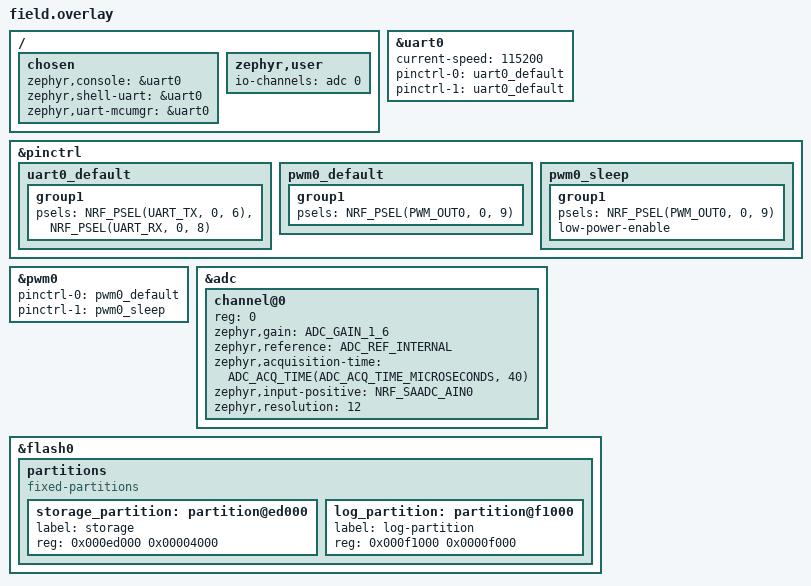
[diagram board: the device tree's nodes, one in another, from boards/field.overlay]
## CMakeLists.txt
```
cmake_minimum_required(VERSION 3.20.0)
find_package(Zephyr REQUIRED HINTS $ENV{ZEPHYR_BASE})
project(smart_lock)
target_sources(app PRIVATE
    src/main.c
    src/lock_hw_zephyr.c
    src/ble_gatt.c
    src/motor.c
    src/battery.c
    src/build_info.c
    src/trinity_wdt.c
    src/trinity_canary.c
    src/trinity_flash.c
    src/trinity_stats.c
    src/trinity_fault.c
    src/trinity_boot.c
)

target_include_directories(app PRIVATE
    ../../include
)
```

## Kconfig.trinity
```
# ==============================================================================
# Kconfig.trinity
# Source from each Zephyr board's root Kconfig: source "Kconfig.trinity"
# IDF and STM32 boards do not use this file -- use CMakeLists.txt instead.
# ==============================================================================

config TRINITY_CHIP_NRF52840
    bool "Trinity: nRF52840 (Zephyr)"
    help
      Selects nRF52840-specific Trinity behaviour in trinity_log_zephyr_nrf.c:
        - Cortex-M4 fault frame (CFSR/HFSR/MMFAR/BFAR/PC/LR/CYC)
        - Boot reason from NRF_POWER->RESETREAS (read + cleared by main)
        - Flash mutex active (NVMC is single-writer, no concurrent access)
        - Pre-init canary in .noinit via SYS_INIT(PRE_KERNEL_1)
        - Heap-allocated stat buffer (avoids .noinit BSS overlap)
        - Bench mode: feeds bootloader WDT channel 0 (cannot be disabled)
      Boards: reed-sensor, smart-lock, smart-light
      Set in prj.conf: CONFIG_TRINITY_CHIP_NRF52840=y

config TRINITY_CHIP_ESP32C3
    bool "Trinity: ESP32-C3 (Zephyr)"
    help
      Selects ESP32-C3-specific Trinity behaviour in trinity_log_zephyr_esp.c:
        - RISC-V fault frame (mepc/ra instead of pc/lr)
        - No flash mutex (ESP32-C3 flash driver serializes internally)
        - Pre-init canary in .noinit via SYS_INIT(PRE_KERNEL_1)
        - Heap-allocated stat buffer (same .noinit overlap protection)
        - Bench mode: WDT skipped entirely (OpenOCD is safety net)
      Boards: pir
      Set in prj.conf: CONFIG_TRINITY_CHIP_ESP32C3=y
```

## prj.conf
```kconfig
# ========================= CORE ==============================================
CONFIG_TRINITY_CHIP_NRF52840=y
CONFIG_PRINTK=y
CONFIG_CONSOLE=y
CONFIG_SERIAL=y
CONFIG_BUILD_OUTPUT_UF2=y

# ========================= HARDWARE ==========================================
CONFIG_ADC=y
CONFIG_PWM=y

# ========================= FLASH / NVS =======================================
CONFIG_FLASH=y
CONFIG_FLASH_MAP=y
CONFIG_FLASH_PAGE_LAYOUT=y
CONFIG_NVS=y
CONFIG_SETTINGS=y
CONFIG_SETTINGS_NVS=y
CONFIG_MPU_ALLOW_FLASH_WRITE=y
CONFIG_STREAM_FLASH=y
CONFIG_SOC_FLASH_NRF_PARTIAL_ERASE=y
CONFIG_SOC_FLASH_NRF_RADIO_SYNC_TICKER=y

# ========================= BLUETOOTH =========================================
CONFIG_BT=y
CONFIG_BT_PERIPHERAL=y
CONFIG_BT_DEVICE_NAME="SmartLock"
CONFIG_BT_GATT_SERVICE_CHANGED=y
CONFIG_BT_LOG_LEVEL_OFF=y

# ========================= STACK SIZES =======================================
CONFIG_ISR_STACK_SIZE=8192
CONFIG_SYSTEM_WORKQUEUE_STACK_SIZE=3072
CONFIG_MAIN_STACK_SIZE=8192
CONFIG_LOG_PROCESS_THREAD_STACK_SIZE=1024

# ========================= FAULT COVERAGE ====================================
CONFIG_HW_STACK_PROTECTION=y
CONFIG_FAULT_DUMP=2
CONFIG_FRAME_POINTER=y
CONFIG_REBOOT=y

# ========================= LOGGING ===========================================
CONFIG_LOG=y
CONFIG_LOG_DEFAULT_LEVEL=3
CONFIG_LOG_MODE_DEFERRED=y
CONFIG_LOG_BUFFER_SIZE=16384

# ========================= THREAD VISIBILITY =================================
CONFIG_THREAD_NAME=y
CONFIG_THREAD_STACK_INFO=y
CONFIG_INIT_STACKS=y

# ========================= TRINITY WATCHDOG ==================================
CONFIG_WATCHDOG=y

# ========================= TRINITY HEAP STATS ================================
CONFIG_SYS_HEAP_RUNTIME_STATS=y
CONFIG_HEAP_MEM_POOL_SIZE=4096

# ========================= TRINITY THREAD STATS ==============================
CONFIG_THREAD_ANALYZER=y
CONFIG_THREAD_ANALYZER_USE_PRINTK=n
CONFIG_THREAD_ANALYZER_AUTO=n
CONFIG_THREAD_RUNTIME_STATS=y
CONFIG_WDT_DISABLE_AT_BOOT=n
```

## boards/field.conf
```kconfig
CONFIG_UART_CONSOLE=y
CONFIG_UART_INTERRUPT_DRIVEN=y
CONFIG_NRFX_UARTE0=y
CONFIG_WDT_DISABLE_AT_BOOT=y
CONFIG_WATCHDOG=y
CONFIG_USB_DEVICE_STACK_NEXT=n
CONFIG_USBD_CDC_ACM_CLASS=n
CONFIG_USB_DEVICE_STACK=n
CONFIG_USE_SEGGER_RTT=n
CONFIG_RTT_CONSOLE=n
CONFIG_LOG_BACKEND_RTT=n
```

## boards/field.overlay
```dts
/*******************************************************************************
 * \file field.overlay
 * \author MichaelLynnCSU (https://github.com/MichaelLynnCSU)
 * \date 01-01-2025
 *
 * \brief Field mode devicetree overlay for Pro Micro nRF52840 smart lock.
 *
 * \note    P0.29 vbat-div-en removed (2026-04-27):
 *          Low-side GND switch removed from hardware. Divider hardwired
 *          directly to GND. P0.29 node removed from overlay.
 *******************************************************************************/
/delete-node/ &storage_partition;

/ {
    chosen {
        zephyr,console = &uart0;
        zephyr,shell-uart = &uart0;
        zephyr,uart-mcumgr = &uart0;
    };

    zephyr,user {
        io-channels = <&adc 0>;
    };
};

&uart0 {
    status = "okay";
    current-speed = <115200>;
    pinctrl-0 = <&uart0_default>;
    pinctrl-1 = <&uart0_default>;
    pinctrl-names = "default", "sleep";
};

&pinctrl {
    uart0_default: uart0_default {
        group1 {
            psels = <NRF_PSEL(UART_TX, 0, 6)>,
                    <NRF_PSEL(UART_RX, 0, 8)>;
        };
    };
    pwm0_default: pwm0_default {
        group1 {
            psels = <NRF_PSEL(PWM_OUT0, 0, 9)>;
        };
    };
    pwm0_sleep: pwm0_sleep {
        group1 {
            psels = <NRF_PSEL(PWM_OUT0, 0, 9)>;
            low-power-enable;
        };
    };
};

&pwm0 {
    status = "okay";
    pinctrl-0 = <&pwm0_default>;
    pinctrl-1 = <&pwm0_sleep>;
    pinctrl-names = "default", "sleep";
};

&adc {
    status = "okay";
    #address-cells = <1>;
    #size-cells = <0>;
    channel@0 {
        reg = <0>;
        zephyr,gain = "ADC_GAIN_1_6";
        zephyr,reference = "ADC_REF_INTERNAL";
        zephyr,acquisition-time = <ADC_ACQ_TIME(ADC_ACQ_TIME_MICROSECONDS, 40)>;
        zephyr,input-positive = <NRF_SAADC_AIN0>; /* P0.02 -- Vbat/3 via 200k/100k divider */
        zephyr,resolution = <12>;
    };
};

&flash0 {
    partitions {
        compatible = "fixed-partitions";
        #address-cells = <1>;
        #size-cells = <1>;
        storage_partition: partition@ed000 {
            label = "storage";
            reg = <0x000ed000 0x00004000>;
        };
        log_partition: partition@f1000 {
            label = "log-partition";
            reg = <0x000f1000 0x0000f000>;
        };
    };
};
```

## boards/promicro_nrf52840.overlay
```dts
/*******************************************************************************
 * \file promicro_nrf52840.overlay
 * \author MichaelLynnCSU (https://github.com/MichaelLynnCSU)
 * \date 01-01-2025
 *
 * \brief Base devicetree overlay for Pro Micro nRF52840 smart lock node.
 *
 * \details Configures:
 *          - ADC channel 0: P0.02 (AIN0) 12-bit, 1/6 gain, internal ref
 *          - PWM0: P0.09 motor control
 *          - Flash partitions:
 *            storage_partition @ 0xED000 (16KB) NVS settings
 *            log_partition     @ 0xF1000 (60KB) flash event log
 *
 * \note    P0.29 vbat-div-en removed (2026-04-27):
 *          Low-side GND switch removed from hardware. Divider bottom
 *          resistor hardwired directly to GND. P0.29 node removed.
 *          21uA quiescent draw negligible vs motor and BLE current.
 *******************************************************************************/
/delete-node/ &storage_partition;

/ {
    zephyr,user {
        io-channels = <&adc 0>;
    };
};

&pwm0 {
    status = "okay";
    pinctrl-0 = <&pwm0_default>;
    pinctrl-1 = <&pwm0_sleep>;
    pinctrl-names = "default", "sleep";
};

&pinctrl {
    pwm0_default: pwm0_default {
        group1 {
            psels = <NRF_PSEL(PWM_OUT0, 0, 9)>;
        };
    };
    pwm0_sleep: pwm0_sleep {
        group1 {
            psels = <NRF_PSEL(PWM_OUT0, 0, 9)>;
            low-power-enable;
        };
    };
};

&adc {
    status = "okay";
    #address-cells = <1>;
    #size-cells = <0>;
    channel@0 {
        reg = <0>;
        zephyr,gain = "ADC_GAIN_1_6";
        zephyr,reference = "ADC_REF_INTERNAL";
        zephyr,acquisition-time = <ADC_ACQ_TIME(ADC_ACQ_TIME_MICROSECONDS, 40)>;
        zephyr,input-positive = <NRF_SAADC_AIN0>; /* P0.02 -- Vbat/3 via 200k/100k divider */
        zephyr,resolution = <12>;
    };
};

&flash0 {
    partitions {
        compatible = "fixed-partitions";
        #address-cells = <1>;
        #size-cells = <1>;
        storage_partition: partition@ed000 {
            label = "storage";
            reg = <0x000ed000 0x00004000>;
        };
        log_partition: partition@f1000 {
            label = "log-partition";
            reg = <0x000f1000 0x0000f000>;
        };
    };
};
```

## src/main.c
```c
/******************************************************************************
 * \file    main.c
 * \author  MichaelLynnCSU (https://github.com/MichaelLynnCSU)
 * \date    01-01-2025
 *
 * \brief   nRF52840 smart lock entry point.
 *
 * \note    WDT main-loop fix (2026-03-23):
 *          WDT kicked unconditionally every 2s in main loop.
 *
 * \note    Field boot WDT fix (2026-03-31):
 *          Field/USB: trinity_wdt_init() before first printk -- UART TX
 *          blocks long enough for bootloader WDT CRV=1 to fire.
 *          Bench: trinity_wdt_init() after trinity_log_init().
 *
 * \note    Deferred dump fix (2026-03-31):
 *          trinity_log_dump_previous() -- bench only, RTT-safe, called early.
 *          trinity_log_dump_previous_deferred() -- field/USB only, UART-safe,
 *          called after WDT is being kicked regularly.
 *
 * \note    NVS WDT kicks (2026-03-31):
 *          trinity_wdt_kick() before and after settings_subsys_init().
 *          Flash erase on first boot exceeds bootloader WDT window.
 *
 * \note    RESETREAS clear fix (2026-03-27):
 *          Read and cleared at very top of main() before anything else.
 *          Latched OR-history register -- stale bits survive across boots
 *          without explicit clear.
 *
 * \note    Flash concurrency fix (2026-03-24):
 *          save_lock_state() in ble_gatt.c wraps settings_save_one()
 *          with trinity_flash_lock/unlock(). See ble_gatt.c for details.
 ******************************************************************************/

#include <zephyr/kernel.h>
#include <zephyr/settings/settings.h>
#include <zephyr/logging/log.h>
#include <zephyr/sys/printk.h>
#include <nrf.h>
#include "lock_hw.h"
#include "ble_gatt.h"
#include "motor.h"
#include "battery.h"
#include "trinity_log.h"
#include "config.h"

LOG_MODULE_REGISTER(smartlock_main, LOG_LEVEL_DBG);

static bool     g_nvs_available = false;
static uint8_t  g_lock_state    = 0;

/*----------------------------------------------------------------------------*/

static int lock_state_set(const char *key, size_t len,
                           settings_read_cb read_cb, void *cb_arg)
{
    if (len != sizeof(g_lock_state)) { return -EINVAL; }
    read_cb(cb_arg, &g_lock_state, sizeof(g_lock_state));
    return 0;
}

SETTINGS_STATIC_HANDLER_DEFINE(lock, "lock", NULL, lock_state_set, NULL, NULL);

/*----------------------------------------------------------------------------*/

int main(void)
{
    int      err          = 0;
    int      mv           = 0;
    uint8_t  soc          = 0;
    uint32_t reset_reason = 0;

    reset_reason         = NRF_POWER->RESETREAS;
    NRF_POWER->RESETREAS = 0xFFFFFFFF;

#if !defined(CONFIG_TRINITY_MODE_BENCH)
    g_init_stage = TRINITY_STAGE_WDT_INIT;
    trinity_wdt_init();
    trinity_wdt_kick();
#endif

    printk("=== SmartLock Boot ===\n");

    trinity_log_dump_previous();

    g_init_stage = TRINITY_STAGE_GPIO;

    err = lock_hw_init();
    if (0 != err) { return err; }

    err = motor_init();
    if (0 != err) { return err; }

    g_init_stage = TRINITY_STAGE_BATTERY;

    if (0 == battery_init())
    {
        mv = battery_read_mv();
        if (0 < mv)
        {
            soc = mv_to_soc(mv);
            printk("[BATT] Initial: %d%% (%d mV)\n", soc, mv);
        }
    }
    else
    {
        printk("[BATT] Init failed\n");
    }

    g_init_stage = TRINITY_STAGE_NVS_INIT;

    trinity_wdt_kick();
    if (0 == settings_subsys_init())
    {
        g_nvs_available = true;
        trinity_wdt_kick();

        g_init_stage = TRINITY_STAGE_NVS_LOAD;

        settings_load();
        printk("NVS ready, lock_state=%d\n", g_lock_state);
    }
    else
    {
        LOG_WRN("NVS init failed");
    }
    trinity_wdt_kick();

    lock_hw_set_led(g_lock_state ? 1 : 0);

    g_init_stage = TRINITY_STAGE_LOG_INIT;

    if (0 == trinity_log_init())
    {
        trinity_log_boot_reason(reset_reason);
        battery_print_status();
    }
    trinity_wdt_kick();

    trinity_log_dump_previous_deferred();

#if defined(CONFIG_TRINITY_MODE_BENCH)
    g_init_stage = TRINITY_STAGE_WDT_INIT;
    trinity_wdt_init();
    trinity_wdt_kick();
#endif

    g_init_stage = TRINITY_STAGE_BT_ENABLE;

    ble_set_lock_state(g_lock_state);
    ble_set_batt(soc);

    err = ble_gatt_init();
    if (0 != err) { return err; }

    g_init_stage = TRINITY_STAGE_MAIN_LOOP;

    while (1)
    {
        trinity_wdt_kick();
        k_sleep(K_MSEC(2000));
    }

    return 0;
}
```

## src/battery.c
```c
/******************************************************************************
 * \file    battery.c
 * \author  MichaelLynnCSU (https://github.com/MichaelLynnCSU)
 * \date    01-01-2025
 *
 * \brief   Battery voltage measurement for nRF52840 smart lock node.
 *
 * \details Reads 4×AA battery voltage via ADC through a resistor divider
 *          with the bottom resistor hardwired to GND.
 *
 *          Hardware:
 *          - ADC channel: zephyr_user node index 0, P0.02 (AIN0)
 *          - Divider: Vbat → 100k → 100k → ┬ → P0.02 (AIN0)
 *                                           └ → 100k → GND (hardwired)
 *          - R1 = 200k (two 100k in series), R2 = 100k
 *          - Ratio: R2/(R1+R2) = 100k/300k = 1/3
 *          - Reconstruct: adc_pin_mV × 3 = Vbat_mV
 *          - ADC: 12-bit, ADC_GAIN_1_6, ADC_REF_INTERNAL (0.6V)
 *          - Max ADC input: 3.6V (0.6V / (1/6) gain)
 *          - 4×AA fresh ~6400mV → ADC pin ~2133mV → within 3.6V max ✓
 *          - Always-on quiescent draw: 6.4V / 300k ≈ 21µA
 *            4×AA ~880mAh total → ~5 years at idle quiescent only
 *
 * \note    Why P0.29 low-side switch was removed (2026-04-27):
 *
 *          Previous design used P0.29 as a low-side GND sink to eliminate
 *          quiescent draw during sleep. Removed because:
 *          - 21µA quiescent is negligible vs. motor, solenoid, and BLE draw
 *          - Removes GPIO dependency and overlay node from battery driver
 *          - Eliminates enable/settle/disable sequencing in firmware
 *          - Settle time concern remains: 10ms busy-wait retained because
 *            source impedance (300k) is unchanged
 *
 *          Earlier history: the original design wired P0.29 into the
 *          high-voltage side of the divider (Vbat → P0.29 → resistors →
 *          AIN0). With 4×AA fresh at ~6.4V this applied 6.4V to an IO pin
 *          rated for 3.3V max. ESD diodes on P0.29 clamped into the 3.3V
 *          rail, damaging the onboard regulator and permanently disabling
 *          USB on two boards. The low-side switch fixed the overvoltage
 *          issue; the hardwired GND removes the switch entirely.
 *
 * \note    k_sleep -> k_busy_wait (2026-03-27):
 *          battery_read_mv() is called from batt_work_handler which runs on
 *          sysworkq. k_sleep() must never be called from a work queue handler
 *          -- it blocks the entire sysworkq thread, corrupting the work
 *          queue's internal scheduler state when the next work item tries to
 *          execute. Confirmed crash: PC=0x5954494E ("NITY"),
 *          SP=0x003BA538 (corrupt), occurring at exactly 300s (first
 *          batt_work fire, BATT_UPDATE_SEC).
 *          Fix: replaced k_sleep(K_MSEC(1)) with k_busy_wait(1000).
 *          k_busy_wait() spins the CPU without yielding the thread, safe
 *          from any context including work queue handlers and ISRs.
 *
 * \note    Settle time 10ms (2026-04-07):
 *          Increased from 1ms to 10ms. The divider source impedance is 300k
 *          (R1+R2 in series from the ADC pin's perspective). At 1ms the ADC
 *          input capacitance has insufficient time to charge through 300k,
 *          producing low readings. 10ms gives a stable result across
 *          temperature. 10ms busy-wait on a 300s read cycle is negligible.
 ******************************************************************************/

#include "battery.h"
#include <zephyr/kernel.h>
#include <zephyr/drivers/adc.h>
#include <zephyr/logging/log.h>
#include <stdio.h>
#include "trinity_log.h"

LOG_MODULE_REGISTER(battery, LOG_LEVEL_INF);

/* ADC channel config from overlay */
static const struct adc_dt_spec adc_channel =
    ADC_DT_SPEC_GET_BY_IDX(DT_PATH(zephyr_user), 0);

/* Voltage divider ratio: R2/(R1+R2) = 100k/300k = 1/3 */
#define DIVIDER_RATIO_NUM    1
#define DIVIDER_RATIO_DEN    3

/* ADC input settle time -- 10ms required for 300k source impedance */
#define ADC_SETTLE_US        10000

#define VBAT_BUF_SIZE        48

int battery_init(void)
{
    if (!adc_is_ready_dt(&adc_channel))
    {
        LOG_ERR("ADC not ready");
        return -1;
    }
    if (adc_channel_setup_dt(&adc_channel) != 0)
    {
        LOG_ERR("ADC channel setup failed");
        return -1;
    }

    LOG_INF("Battery init OK (AIN0/P0.02, hardwired GND divider)");
    return 0;
}

int battery_read_mv(void)
{
    int16_t  raw     = 0;
    int32_t  mv      = 0;
    int      err     = 0;
    int      vbat_mv = 0;

    struct adc_sequence seq =
    {
        .buffer      = &raw,
        .buffer_size = sizeof(raw),
    };

    adc_sequence_init_dt(&adc_channel, &seq);

    /* 10ms settle: allow ADC input cap to charge through 300k source.
     * k_busy_wait() used -- safe from sysworkq context. See note above. */
    k_busy_wait(ADC_SETTLE_US);

    trinity_wdt_kick();
    err = adc_read_dt(&adc_channel, &seq);
    trinity_wdt_kick();

    if (err != 0)
    {
        LOG_ERR("ADC read failed: %d", err);
        return -1;
    }

    mv = (int32_t)raw;
    adc_raw_to_millivolts_dt(&adc_channel, &mv);

    /* Reconstruct Vbat: ADC pin sees Vbat/3, multiply back by 3 */
    vbat_mv = (int)(mv * DIVIDER_RATIO_DEN / DIVIDER_RATIO_NUM);

    LOG_INF("raw=%d adc_pin_mv=%d vbat_mv=%d", raw, (int)mv, vbat_mv);

    return vbat_mv;
}

void battery_print_status(void)
{
    char        vbat_buf[VBAT_BUF_SIZE] = {0};
    const char *status                  = NULL;
    int         vbat_mv                 = 0;

    vbat_mv = battery_read_mv();
    if (0 > vbat_mv)
    {
        LOG_ERR("Battery read failed");
        return;
    }

    (void)snprintf(vbat_buf, sizeof(vbat_buf),
                   "EVENT: BOOT | VBAT: %d mV\n", vbat_mv);
    trinity_log_event(vbat_buf);

    if      (vbat_mv >= VBAT_LOW_MV)      { status = "GOOD";     }
    else if (vbat_mv >= VBAT_CRITICAL_MV) { status = "LOW";      }
    else if (vbat_mv >= VBAT_DEAD_MV)     { status = "CRITICAL"; }
    else                                   { status = "DEAD";     }

    LOG_INF("VBAT: %d mV (%s)", vbat_mv, status);
}
```

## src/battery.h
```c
#pragma once
#include <stdint.h>

/* 4×AA discharge range in mV.
 * VBAT_FULL_MV = 6400: four fresh AA cells at ~1.6V each.
 * VBAT_DEAD_MV = 4400: cutoff below which cells are considered dead.
 * Usable window: 2000mV. */
#define VBAT_FULL_MV      6400
#define VBAT_LOW_MV       5200
#define VBAT_CRITICAL_MV  4800
#define VBAT_DEAD_MV      4400
#define VBAT_RANGE_MV     (VBAT_FULL_MV - VBAT_DEAD_MV)

/* Voltage divider ratio: Vbat → 100k → 100k → AIN0
 *                                              └ → 100k → GND
 * R1 = 200k (two 100k in series), R2 = 100k
 * Ratio = R2 / (R1 + R2) = 100k / 300k = 1/3
 * Reconstruct: adc_pin_mV × DIVIDER_RATIO_DEN = Vbat_mV */
#define DIVIDER_RATIO_NUM  1
#define DIVIDER_RATIO_DEN  3

static inline uint8_t mv_to_soc(int mv)
{
    if (mv >= VBAT_FULL_MV) { return 100u; }
    if (mv <= VBAT_DEAD_MV) { return 0u;   }
    return (uint8_t)((mv - VBAT_DEAD_MV) * 100 / VBAT_RANGE_MV);
}

int  battery_init(void);
int  battery_read_mv(void);
void battery_print_status(void);
```

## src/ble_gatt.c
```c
/******************************************************************************
 * \file    ble_gatt.c
 * \author  MichaelLynnCSU (https://github.com/MichaelLynnCSU)
 * \date    01-01-2025
 *
 * \brief   BLE GATT service and advertising for nRF52840 smart lock node.
 *
 * \details Connectable BLE peripheral. Exposes lock control, heartbeat,
 *          and battery level characteristics. Advertisement carries
 *          manufacturer data with lock state and battery SOC for passive
 *          hub BLE scanning.
 *
 *          GATT layout:
 *          Service  0x1234
 *            Char   0x1235  lock control   R/W/WWR/Notify
 *            CCC
 *            Char   0x1236  heartbeat      R/Notify
 *            CCC
 *            Char   0x2A19  battery level  R/Notify
 *            CCC
 *
 *          Lock state machine (lock_state.h):
 *          lock_write() validates commands via lock_state_transition().
 *          Commands are rejected while motor is moving (UNLOCKING/LOCKING).
 *          motor.c calls ble_lock_settle() when motor_off_timer fires —
 *          advances UNLOCKING->UNLOCKED or LOCKING->LOCKED, notifies BLE,
 *          updates adv, and saves settled state to settings.
 *
 * \note    Flash concurrency fix (2026-03-24):
 *          lock_write() calls save_lock_state() which wraps settings_save_one()
 *          with trinity_flash_lock/unlock() to prevent concurrent NVMC
 *          access with trinity_log_event() on sysworkq.
 *
 * \note    BT RX WQ stack fix (2026-03-24):
 *          lock_write() submits motor_drive() via work item -- never
 *          blocks BT RX WQ. k_sleep removed from this path entirely.
 *
 * \note    Definition order (circular dependency):
 *          BT_GATT_SERVICE_DEFINE and the GATT handlers cannot be naively
 *          reordered to resolve the forward-reference problem because the
 *          dependency is circular: the service definition requires the handler
 *          addresses in its static struct initializer, while lock_write()
 *          requires smartlock_svc to already be declared so it can take
 *          &smartlock_svc.attrs[2]. Whichever is placed first, the other is
 *          not yet in scope. BT_GATT_SERVICE_DEFINE both declares and defines
 *          the symbol in one macro expansion with no forward-declaration form,
 *          so the only lever available is forward-declaring the handlers above
 *          the service definition. A static function pointer in an initializer
 *          only requires a prior declaration, not a full definition.
 ******************************************************************************/

#include "ble_gatt.h"
#include "motor.h"
#include "config.h"
#include "battery.h"
#include "trinity_log.h"
#include "lock_state.h"
#include <zephyr/kernel.h>
#include <zephyr/bluetooth/bluetooth.h>
#include <zephyr/bluetooth/gap.h>
#include <zephyr/bluetooth/gatt.h>
#include <zephyr/bluetooth/conn.h>
#include <zephyr/settings/settings.h>
#include <zephyr/logging/log.h>
#include <zephyr/sys/printk.h>

LOG_MODULE_REGISTER(ble_gatt, LOG_LEVEL_DBG);

/** \brief Lock state machine — authoritative lock state for this node */
static LOCK_STATE_E g_lock_state    = LOCK_STATE_LOCKED;
static uint8_t      lock_batt_soc   = 0;
static uint8_t      heartbeat_val   = 1;
static uint64_t     last_lock_activity = 0;

static uint8_t lock_mfg_data[MFG_DATA_SIZE] = {MFG_COMPANY_ID, 0x00, 0x00, 0x00};
static uint8_t heartbeat_counter = 0; /**< incremented on every heartbeat tick,
                                        *   written into lock_mfg_data[MFG_HEARTBEAT_IDX]
                                        *   so passive scanners see liveness. */

static struct bt_data adv_data[] =
{
    BT_DATA_BYTES(BT_DATA_FLAGS, (BT_LE_AD_GENERAL | BT_LE_AD_NO_BREDR)),
    BT_DATA(BT_DATA_NAME_COMPLETE,
            CONFIG_BT_DEVICE_NAME, sizeof(CONFIG_BT_DEVICE_NAME) - 1),
    BT_DATA_BYTES(BT_DATA_UUID16_ALL, 0x34, 0x12),
    BT_DATA(BT_DATA_MANUFACTURER_DATA, lock_mfg_data, sizeof(lock_mfg_data)),
};

/*----------------------------------------------------------------------------*/
/* Forward declarations                                                        */

static ssize_t lock_read   (struct bt_conn *, const struct bt_gatt_attr *,
                             void *, uint16_t, uint16_t);
static ssize_t lock_write  (struct bt_conn *, const struct bt_gatt_attr *,
                             const void *, uint16_t, uint16_t, uint8_t);
static ssize_t lock_hb_read(struct bt_conn *, const struct bt_gatt_attr *,
                             void *, uint16_t, uint16_t);
static ssize_t batt_read   (struct bt_conn *, const struct bt_gatt_attr *,
                             void *, uint16_t, uint16_t);
static void    hb_ccc_changed(const struct bt_gatt_attr *, uint16_t);

BT_GATT_SERVICE_DEFINE(smartlock_svc,
    BT_GATT_PRIMARY_SERVICE(BT_UUID_DECLARE_16(0x1234)),
    BT_GATT_CHARACTERISTIC(BT_UUID_DECLARE_16(0x1235),
        BT_GATT_CHRC_READ | BT_GATT_CHRC_WRITE |
        BT_GATT_CHRC_WRITE_WITHOUT_RESP | BT_GATT_CHRC_NOTIFY,
        BT_GATT_PERM_READ | BT_GATT_PERM_WRITE,
        lock_read, lock_write, NULL),
    BT_GATT_CCC(NULL, BT_GATT_PERM_READ | BT_GATT_PERM_WRITE),
    BT_GATT_CHARACTERISTIC(BT_UUID_DECLARE_16(0x1236),
        BT_GATT_CHRC_READ | BT_GATT_CHRC_NOTIFY,
        BT_GATT_PERM_READ,
        lock_hb_read, NULL, &heartbeat_val),
    BT_GATT_CCC(hb_ccc_changed, BT_GATT_PERM_READ | BT_GATT_PERM_WRITE),
    BT_GATT_CHARACTERISTIC(BT_UUID_DECLARE_16(0x2A19),
        BT_GATT_CHRC_READ | BT_GATT_CHRC_NOTIFY,
        BT_GATT_PERM_READ,
        batt_read, NULL, &lock_batt_soc),
    BT_GATT_CCC(NULL, BT_GATT_PERM_READ | BT_GATT_PERM_WRITE),
);

/*----------------------------------------------------------------------------*/

static ssize_t lock_read(struct bt_conn *conn,
                          const struct bt_gatt_attr *attr,
                          void *buf, uint16_t len, uint16_t offset)
{
    uint8_t ble_val = lock_state_to_ble(g_lock_state);

    return bt_gatt_attr_read(conn, attr, buf, len, offset,
                             &ble_val, sizeof(ble_val));
}

static ssize_t lock_hb_read(struct bt_conn *conn,
                              const struct bt_gatt_attr *attr,
                              void *buf, uint16_t len, uint16_t offset)
{
    return bt_gatt_attr_read(conn, attr, buf, len, offset,
                             &heartbeat_val, sizeof(heartbeat_val));
}

static ssize_t batt_read(struct bt_conn *conn,
                          const struct bt_gatt_attr *attr,
                          void *buf, uint16_t len, uint16_t offset)
{
    return bt_gatt_attr_read(conn, attr, buf, len, offset,
                             &lock_batt_soc, sizeof(lock_batt_soc));
}

/******************************************************************************
 * \brief GATT write handler for lock control characteristic (0x1235).
 *
 * \details Routes command through lock state machine. Rejects write if
 *          motor is currently moving (UNLOCKING or LOCKING state).
 *          On valid transition: logs event via Trinity, drives motor,
 *          updates BLE adv with transitional state. Settled state is
 *          written to settings only after motor_off_timer fires via
 *          ble_lock_settle().
 *
 * \author MichaelLynnCSU (https://github.com/MichaelLynnCSU)
 ******************************************************************************/
static ssize_t lock_write(struct bt_conn *conn,
                           const struct bt_gatt_attr *attr,
                           const void *buf, uint16_t len,
                           uint16_t offset, uint8_t flags)
{
    const uint8_t *p_buf   = (const uint8_t *)buf;
    uint8_t        val       = 0;
    uint16_t       tx_id     = 0; /**< hub-stamped command counter;
                                   *   0 = old hub firmware, 1-byte write */
    LOCK_STATE_E old_state = LOCK_STATE_LOCKED;
    LOCK_STATE_E new_state = LOCK_STATE_LOCKED;
    const char  *p_ev      = NULL;

    if (LOCK_WRITE_LEN != len)
    {
        return BT_GATT_ERR(BT_ATT_ERR_INVALID_ATTRIBUTE_LEN);
    }

    val   = p_buf[LOCK_WRITE_STATE_IDX];
    tx_id = (uint16_t)p_buf[LOCK_WRITE_TX_ID_LO_IDX] |
            ((uint16_t)p_buf[LOCK_WRITE_TX_ID_HI_IDX] << 8);

    old_state = g_lock_state;
    new_state = lock_state_transition(old_state, val);

    if (new_state == old_state)
    {
        if (lock_state_is_busy(old_state))
        {
            printk("[LOCK] tx_id=%u command rejected — motor moving (%s)\n",
                   (unsigned)tx_id, lock_state_label(old_state));
            trinity_log_event("EVENT: LOCK_CMD_REJECTED\n");
        }
        else
        {
            printk("[LOCK] tx_id=%u command ignored — already in state %s\n",
                   (unsigned)tx_id, lock_state_label(old_state));
        }
        return len;
    }

    g_lock_state       = new_state;
    last_lock_activity = k_uptime_get();

    p_ev = lock_state_event_str(new_state);
    if (NULL != p_ev)
    {
        trinity_log_event(p_ev);
    }

    printk("[LOCK] tx_id=%u %s -> %s (cmd=%d)\n",
           (unsigned)tx_id,
           lock_state_label(old_state),
           lock_state_label(new_state),
           val);

    ble_adv_update();

    uint8_t ble_val = lock_state_to_ble(new_state);
    bt_gatt_notify(NULL, &smartlock_svc.attrs[2], &ble_val, sizeof(ble_val));

    motor_drive(val);

    return len;
}
/*----------------------------------------------------------------------------*/

/******************************************************************************
 * \brief Called by motor.c when motor_off_timer fires — settle lock state.
 *
 * \return void
 *
 * \details Advances UNLOCKING->UNLOCKED or LOCKING->LOCKED. Saves settled
 *          state to settings, notifies BLE client, updates adv.
 *          Called from timer ISR context via k_work — safe for settings
 *          and BLE notify.
 *
 * \author MichaelLynnCSU (https://github.com/MichaelLynnCSU)
 ******************************************************************************/
void ble_lock_settle(void)
{
    LOCK_STATE_E old_state = g_lock_state;               /**< pre-settle state */
    LOCK_STATE_E new_state = lock_state_settle(old_state); /**< settled state */
    const char  *p_ev      = NULL;                        /**< trinity event */
    uint8_t      ble_val   = 0;                           /**< BLE raw value */

    if (new_state == old_state)
    {
        return;
    }

    g_lock_state = new_state;
    ble_val      = lock_state_to_ble(new_state);

    p_ev = lock_state_event_str(new_state);
    if (NULL != p_ev)
    {
        trinity_log_event(p_ev);
    }

    printk("[LOCK] Settled: %s -> %s\n",
           lock_state_label(old_state),
           lock_state_label(new_state));

    /* Save settled state to persistent settings */
    trinity_flash_lock();
    settings_save_one("lock/state", &ble_val, sizeof(ble_val));
    trinity_flash_unlock();

    /* Notify BLE client and update adv with settled state */
    bt_gatt_notify(NULL, &smartlock_svc.attrs[2], &ble_val, sizeof(ble_val));
    ble_adv_update();
}

/*----------------------------------------------------------------------------*/

static void hb_ccc_changed(const struct bt_gatt_attr *attr, uint16_t value)
{
    printk("[HB] CCC changed: %d\n", value);
}

/*----------------------------------------------------------------------------*/

void ble_adv_update(void)
{
    uint8_t ble_val = lock_state_to_ble(g_lock_state);

    lock_mfg_data[MFG_LOCK_STATE_IDX] = ble_val;
    lock_mfg_data[MFG_BATT_IDX]       = lock_batt_soc;
    lock_mfg_data[MFG_HEARTBEAT_IDX]  = heartbeat_counter;
    bt_le_adv_update_data(adv_data, ARRAY_SIZE(adv_data), NULL, 0);
}

void ble_set_batt(uint8_t soc)
{
    lock_batt_soc = soc;
    bt_gatt_notify(NULL, &smartlock_svc.attrs[8],
                   &lock_batt_soc, sizeof(lock_batt_soc));
    ble_adv_update();
}

void ble_set_lock_state(uint8_t state)
{
    g_lock_state = (LOCK_STATE_E)state;
    ble_adv_update();
}

/*----------------------------------------------------------------------------*/

static struct k_work g_adv_restart_work;
static struct k_work g_hb_work;
static struct k_work g_batt_work;
static struct k_work g_stats_work;

static void adv_restart_handler(struct k_work *work)
{
    static const struct bt_le_adv_param param =
    {
        .id           = BT_ID_DEFAULT,
        .options      = BT_LE_ADV_OPT_CONN,
        .interval_min = BT_GAP_ADV_SLOW_INT_MIN,
        .interval_max = BT_GAP_ADV_SLOW_INT_MAX,
    };

    int err = bt_le_adv_start(&param, adv_data, ARRAY_SIZE(adv_data), NULL, 0);
    if (0 != err) { printk("[BLE] Adv restart failed: %d\n", err); }
    else          { printk("[BLE] Advertising restarted\n"); }
}

static void hb_work_handler(struct k_work *work)
{
    uint64_t now = k_uptime_get();

    if ((now - last_lock_activity) > (IDLE_HEARTBEAT_SEC * 1000ULL))
    {
        heartbeat_counter++;

        /* GATT notify still fires for any connected/subscribed client. */
        int err = bt_gatt_notify(NULL, &smartlock_svc.attrs[5],
                                 &heartbeat_val, sizeof(heartbeat_val));
        if (err && err != -ENOTCONN) { printk("[HB] Notify failed: %d\n", err); }

        /* Advertising refresh is now the primary passive liveness path --
         * matches reed/temp sensor pattern. Hub sees this without ever
         * connecting. */
        ble_adv_update();
        printk("[HB] Sent (counter=%u)\n", heartbeat_counter);
    }
}

static void batt_work_handler(struct k_work *work)
{
    int mv = battery_read_mv();
    if (0 > mv) { printk("[BATT] Read failed\n"); return; }

    uint8_t soc = mv_to_soc(mv);
    printk("[BATT] raw mv=%d soc=%d%%\n", mv, soc);
    ble_set_batt(soc);
}

static void stats_work_handler(struct k_work *work)
{
    trinity_wdt_kick();
    trinity_log_heap_stats();
    trinity_log_task_stats();
}

static void idle_hb_handler(struct k_timer *t)  { k_work_submit(&g_hb_work);    }
static void batt_handler(struct k_timer *t)      { k_work_submit(&g_batt_work);  }
static void stats_handler(struct k_timer *t)     { k_work_submit(&g_stats_work); }

K_TIMER_DEFINE(g_idle_hb_timer, idle_hb_handler, NULL);
K_TIMER_DEFINE(g_batt_timer,    batt_handler,     NULL);
K_TIMER_DEFINE(g_stats_timer,   stats_handler,    NULL);

/*----------------------------------------------------------------------------*/

static void on_connected(struct bt_conn *conn, uint8_t err)
{
    if (0 != err) { printk("[BLE] Connect failed: %d\n", err); return; }
    printk("[BLE] Connected\n");
}

static void on_disconnected(struct bt_conn *conn, uint8_t reason)
{
    printk("[BLE] Disconnected (reason %d)\n", reason);
    k_work_submit(&g_adv_restart_work);
}

BT_CONN_CB_DEFINE(conn_callbacks) =
{
    .connected    = on_connected,
    .disconnected = on_disconnected,
};

/*----------------------------------------------------------------------------*/

int ble_gatt_init(void)
{
    int err = 0;

    static const struct bt_le_adv_param slow_adv_param =
    {
        .id           = BT_ID_DEFAULT,
        .options      = BT_LE_ADV_OPT_CONN,
        .interval_min = BT_GAP_ADV_SLOW_INT_MIN,
        .interval_max = BT_GAP_ADV_SLOW_INT_MAX,
    };

    err = bt_enable(NULL);
    if (0 != err) { LOG_ERR("BLE init failed"); return err; }
    trinity_wdt_kick();
    LOG_INF("BLE enabled");
    trinity_log_event("EVENT: BLE_READY\n");

    err = bt_le_adv_start(&slow_adv_param,
                           adv_data, ARRAY_SIZE(adv_data), NULL, 0);
    if (0 != err) { LOG_ERR("BLE advertising failed"); return err; }

    trinity_log_event("EVENT: BLE_ADV_START\n");
    ble_adv_update();

    k_work_init(&g_adv_restart_work, adv_restart_handler);
    k_work_init(&g_hb_work,          hb_work_handler);
    k_work_init(&g_batt_work,        batt_work_handler);
    k_work_init(&g_stats_work,       stats_work_handler);

    last_lock_activity = k_uptime_get();

    k_timer_start(&g_idle_hb_timer,
                  K_SECONDS(IDLE_HEARTBEAT_SEC),
                  K_SECONDS(IDLE_HEARTBEAT_SEC));
    k_timer_start(&g_batt_timer,
                  K_SECONDS(BATT_UPDATE_SEC),
                  K_SECONDS(BATT_UPDATE_SEC));
    k_timer_start(&g_stats_timer,
                  K_SECONDS(STATS_INTERVAL_SEC),
                  K_SECONDS(STATS_INTERVAL_SEC));

    return 0;
}
```

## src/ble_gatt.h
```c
/******************************************************************************
 * \file    ble_gatt.h
 * \author  MichaelLynnCSU (https://github.com/MichaelLynnCSU)
 * \date    01-01-2025
 *
 * \brief   BLE GATT service API for nRF52840 smart lock node.
 ******************************************************************************/

#ifndef BLE_GATT_H
#define BLE_GATT_H

#include <stdint.h>
#include "config.h"   /* STATS_INTERVAL_SEC, IDLE_HEARTBEAT_SEC, BATT_UPDATE_SEC,
                         MFG_*, LOCK_WRITE_LEN */

/**
 * \brief Initialise BLE stack, GATT service, and start advertising.
 * \return 0 on success, negative errno on failure.
 */
int ble_gatt_init(void);

/**
 * \brief Update BLE advertisement manufacturer data with current lock
 *        state and battery SOC.
 * \return void
 */
void ble_adv_update(void);

/**
 * \brief Update battery SOC and notify connected client.
 * \param soc - Battery SOC percent (0-100).
 * \return void
 */
void ble_set_batt(uint8_t soc);

/**
 * \brief Set lock state directly (e.g. on boot from settings restore).
 * \param state - Raw lock state value.
 * \return void
 */
void ble_set_lock_state(uint8_t state);

/**
 * \brief Called by motor.c when motor_off_timer fires.
 *        Advances lock state machine UNLOCKING->UNLOCKED or LOCKING->LOCKED.
 *        Saves settled state to settings, notifies BLE client, updates adv.
 * \return void
 */
void ble_lock_settle(void);

#endif /* BLE_GATT_H */
```

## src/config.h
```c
/******************************************************************************
 * \file    config.h
 * \brief   Shared compile-time configuration for the smart-lock node.
 *
 * \details Single authoritative source for timing constants and BLE
 *          manufacturer-data layout used by both main.c and ble_gatt.c.
 *          Include this header instead of defining these macros locally.
 ******************************************************************************/
#ifndef CONFIG_H
#define CONFIG_H

/* ── Timing ────────────────────────────────────────────────────────────────── */
#define STATS_INTERVAL_SEC  60   /**< Statistics report interval (seconds)    */
#define IDLE_HEARTBEAT_SEC  240  /**< Idle heartbeat advertisement (seconds)  */
#define BATT_UPDATE_SEC     300  /**< Battery SOC refresh interval (seconds)  */

/* ── BLE manufacturer data layout ─────────────────────────────────────────── */
#define MFG_DATA_SIZE       4    /**< Total manufacturer data bytes           */
#define MFG_COMPANY_ID      0xAC /**< Registered company ID byte              */
#define MFG_LOCK_STATE_IDX  1    /**< Lock state byte index in mfg data       */
#define MFG_BATT_IDX        2    /**< Battery SOC byte index in mfg data      */
#define MFG_HEARTBEAT_IDX   3    /**< Heartbeat counter byte index in mfg data.
                                   *   Incremented on every heartbeat tick so
                                   *   a passive scanner (hub or app) can see
                                   *   liveness without a GATT connection.   */

/*
 * GATT write payload layout (3 bytes):
 * [0] = state      (0=unlock, 1=lock)
 * [1] = tx_id low byte  (little-endian)
 * [2] = tx_id high byte (little-endian)
 *
 * tx_id is a per-session command counter (RAM only on hub, resets on hub
 * reboot). Correlation key is (MAC + tx_id) within a bounded time window.
 * It is NOT a global unique message ID.
 *
 * Two-phase identity:
 *   tx_id    — generated BEFORE write (command tracking, crosses boundary)
 *   event_id — generated AFTER bus_publish_lock() (hub-internal only)
 *
 * Device logs tx_id only. Hub logs tx_id + event_id mapping.
 * If tx_id exists but no event_id appears in hub log → bus failure.
 * If event_id exists but device did not log tx_id → device failure.
 */
#define LOCK_WRITE_LEN          3
#define LOCK_WRITE_STATE_IDX    0   /**< state byte index in write payload    */
#define LOCK_WRITE_TX_ID_LO_IDX 1   /**< tx_id low byte index                */
#define LOCK_WRITE_TX_ID_HI_IDX 2   /**< tx_id high byte index               */

#endif /* CONFIG_H */
```

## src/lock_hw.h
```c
#ifndef LOCK_HW_H
#define LOCK_HW_H
/**
 * \brief  Initialise lock status LED GPIO.
 * \return 0 on success, negative errno on failure.
 */
int lock_hw_init(void);

/**
 * \brief  Set lock status LED.
 * \param  state  1=on, 0=off.
 */
void lock_hw_set_led(int state);
#endif /* LOCK_HW_H */
```

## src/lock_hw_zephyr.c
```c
/******************************************************************************
 * \file    lock_hw_zephyr.c
 * \brief   Zephyr GPIO binding for smart lock status LED.
 *
 * \details Implements lock_hw.h using Zephyr GPIO API.
 *          All Zephyr driver includes isolated here.
 *          main.c calls through lock_hw.h and has no GPIO dependency.
 ******************************************************************************/

#include "lock_hw.h"
#include <zephyr/drivers/gpio.h>
#include <zephyr/logging/log.h>

LOG_MODULE_DECLARE(smartlock_main, LOG_LEVEL_DBG);

#define LIGHT_NODE DT_ALIAS(led0)

static const struct gpio_dt_spec g_led = GPIO_DT_SPEC_GET(LIGHT_NODE, gpios);

/*----------------------------------------------------------------------------*/

int lock_hw_init(void)
{
    if (!device_is_ready(g_led.port))
    {
        LOG_ERR("LED not ready");
        return -ENODEV;
    }
    return gpio_pin_configure_dt(&g_led, GPIO_OUTPUT_INACTIVE);
}

/*----------------------------------------------------------------------------*/

void lock_hw_set_led(int state)
{
    gpio_pin_set_dt(&g_led, state);
}
```

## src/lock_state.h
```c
/******************************************************************************
 * \file    lock_state.h
 * \author  MichaelLynnCSU (https://github.com/MichaelLynnCSU)
 * \date    01-01-2025
 *
 * \brief   Lock state machine for nRF52840 smart lock node.
 *
 * \details Pure logic — no Zephyr deps, no I/O, no globals, no side effects.
 *          Safe to unit test without hardware or OS dependencies.
 *          Mirrors LOCK_STATE_E and logic_lock_* in BeagleBone
 *          controller_logic.h — both ends model the same transitions.
 *
 *          Valid transitions:
 *          LOCKED    -> UNLOCKING   phone sends unlock (cmd=0)
 *          UNLOCKING -> UNLOCKED    motor_off_timer fires (settle)
 *          UNLOCKED  -> LOCKING     phone sends lock   (cmd=1)
 *          LOCKING   -> LOCKED      motor_off_timer fires (settle)
 *          ANY       -> ERROR       fault detected
 *          ERROR     -> LOCKED      recovery — assume locked for safety
 *
 *          UNLOCKING and LOCKING reject all commands — motor is moving.
 *
 *          Caller owns all side effects:
 *          - BLE GATT notify on transition
 *          - Trinity log event on transition
 *          - motor_drive() call
 *          - BLE adv update
 ******************************************************************************/

#ifndef LOCK_STATE_H
#define LOCK_STATE_H

#include <stdint.h>
#include <stdbool.h>

/******************************* ENUMERATIONS *********************************/

/**
 * \brief Lock state machine states.
 *
 * \details Matches LOCK_STATE_E in BeagleBone controller_logic.h.
 *          Values are stable — stored in settings and sent over BLE adv.
 */
typedef enum
{
    LOCK_STATE_LOCKED    = 0,  /**< locked — idle, accepts unlock command */
    LOCK_STATE_UNLOCKING = 1,  /**< transitioning locked -> unlocked */
    LOCK_STATE_UNLOCKED  = 2,  /**< unlocked — idle, accepts lock command */
    LOCK_STATE_LOCKING   = 3,  /**< transitioning unlocked -> locked */
    LOCK_STATE_ERROR     = 4,  /**< fault — motor or comms error */
} LOCK_STATE_E;

/*************************** STATE MACHINE LOGIC ******************************/

/******************************************************************************
 * \brief Validate and return new lock state for a phone command.
 *
 * \param current - Current lock state.
 * \param cmd     - Requested lock value (1=lock, 0=unlock).
 *
 * \return LOCK_STATE_E - New state if transition valid, current if rejected.
 *
 * \details Rejects all commands while motor is moving (UNLOCKING/LOCKING).
 *          Rejects unlock when already unlocked, lock when already locked.
 *          ERROR only accepts recovery to LOCKED.
 *
 * \author MichaelLynnCSU (https://github.com/MichaelLynnCSU)
 ******************************************************************************/
static inline LOCK_STATE_E lock_state_transition(LOCK_STATE_E current,
                                                  uint8_t      cmd)
{
    switch (current)
    {
        case LOCK_STATE_LOCKED:
            return (0 == cmd) ? LOCK_STATE_UNLOCKING : current;

        case LOCK_STATE_UNLOCKED:
            return (1 == cmd) ? LOCK_STATE_LOCKING : current;

        case LOCK_STATE_ERROR:
            /* safety — only allow recovery to locked */
            return (1 == cmd) ? LOCK_STATE_LOCKED : current;

        case LOCK_STATE_UNLOCKING:
        case LOCK_STATE_LOCKING:
            /* motor moving — reject all commands */
            return current;

        default:
            return LOCK_STATE_ERROR;
    }
}

/******************************************************************************
 * \brief Advance lock state after motor_off_timer confirms movement done.
 *
 * \param current - Current lock state (UNLOCKING or LOCKING).
 *
 * \return LOCK_STATE_E - Settled state after motor stops.
 *
 * \details UNLOCKING -> UNLOCKED, LOCKING -> LOCKED.
 *          All other states returned unchanged.
 *
 * \author MichaelLynnCSU (https://github.com/MichaelLynnCSU)
 ******************************************************************************/
static inline LOCK_STATE_E lock_state_settle(LOCK_STATE_E current)
{
    switch (current)
    {
        case LOCK_STATE_UNLOCKING: return LOCK_STATE_UNLOCKED;
        case LOCK_STATE_LOCKING:   return LOCK_STATE_LOCKED;
        default:                   return current;
    }
}

/******************************************************************************
 * \brief Return true if lock is busy — motor is moving, commands rejected.
 *
 * \param state - Current lock state.
 *
 * \return bool - true if commands should be rejected.
 *
 * \author MichaelLynnCSU (https://github.com/MichaelLynnCSU)
 ******************************************************************************/
static inline bool lock_state_is_busy(LOCK_STATE_E state)
{
    return (LOCK_STATE_UNLOCKING == state) || (LOCK_STATE_LOCKING == state);
}

/******************************************************************************
 * \brief Return Trinity log event string for a lock state transition.
 *
 * \param to - New lock state.
 *
 * \return const char* - Event string for trinity_log_event(), or NULL if
 *                       no event should be logged.
 *
 * \author MichaelLynnCSU (https://github.com/MichaelLynnCSU)
 ******************************************************************************/
static inline const char *lock_state_event_str(LOCK_STATE_E to)
{
    switch (to)
    {
        case LOCK_STATE_LOCKED:    return "EVENT: LOCK\n";
        case LOCK_STATE_UNLOCKED:  return "EVENT: UNLOCK\n";
        case LOCK_STATE_UNLOCKING: return "EVENT: LOCK_UNLOCKING\n";
        case LOCK_STATE_LOCKING:   return "EVENT: LOCK_LOCKING\n";
        case LOCK_STATE_ERROR:     return "EVENT: LOCK_ERROR\n";
        default:                   return NULL;
    }
}

/******************************************************************************
 * \brief Return human-readable label for a lock state.
 *
 * \param state - Lock state value.
 *
 * \return const char* - State label string.
 *
 * \author MichaelLynnCSU (https://github.com/MichaelLynnCSU)
 ******************************************************************************/
static inline const char *lock_state_label(LOCK_STATE_E state)
{
    switch (state)
    {
        case LOCK_STATE_LOCKED:    return "LOCKED";
        case LOCK_STATE_UNLOCKING: return "UNLOCKING";
        case LOCK_STATE_UNLOCKED:  return "UNLOCKED";
        case LOCK_STATE_LOCKING:   return "LOCKING";
        case LOCK_STATE_ERROR:     return "ERROR";
        default:                   return "UNKNOWN";
    }
}

/******************************************************************************
 * \brief Return the raw BLE/settings value for a settled lock state.
 *
 * \param state - Current lock state.
 *
 * \return uint8_t - 1=locked, 0=unlocked, 0xFF=transitioning/error.
 *
 * \details Used to update BLE adv mfg data and settings_save_one().
 *          Only LOCKED and UNLOCKED return meaningful values —
 *          transitional states return 0xFF sentinel.
 *
 * \author MichaelLynnCSU (https://github.com/MichaelLynnCSU)
 ******************************************************************************/
static inline uint8_t lock_state_to_ble(LOCK_STATE_E state)
{
    switch (state)
    {
        case LOCK_STATE_LOCKED:   return 1;
        case LOCK_STATE_UNLOCKED: return 0;
        default:                  return 0xFF; /* transitioning or error */
    }
}

#endif /* LOCK_STATE_H */
```
